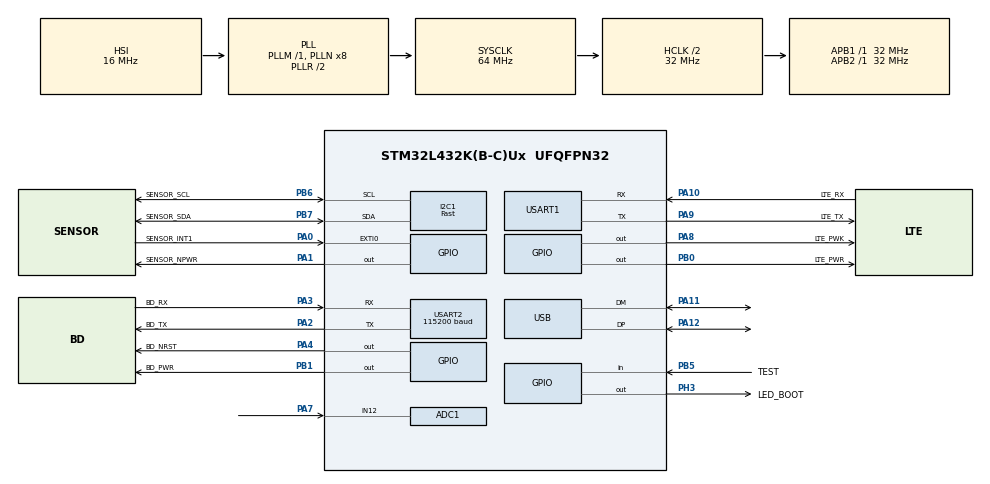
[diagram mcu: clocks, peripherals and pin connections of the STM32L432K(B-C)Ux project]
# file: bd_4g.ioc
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ADC1.Channel-0\#ChannelRegularConversion=ADC_CHANNEL_12
ADC1.Channel-1\#ChannelRegularConversion=ADC_CHANNEL_TEMPSENSOR
ADC1.Channel-2\#ChannelRegularConversion=ADC_CHANNEL_VBAT
ADC1.Channel-3\#ChannelRegularConversion=ADC_CHANNEL_VREFINT
ADC1.ClockPrescaler=ADC_CLOCK_ASYNC_DIV4
ADC1.ContinuousConvMode=ENABLE
ADC1.DMAContinuousRequests=ENABLE
ADC1.EOCSelection=ADC_EOC_SEQ_CONV
ADC1.EnableAnalogWatchDog1=false
ADC1.LowPowerAutoWait=DISABLE
ADC1.NbrOfConversion=4
ADC1.NbrOfConversionFlag=1
ADC1.OffsetNumber-0\#ChannelRegularConversion=ADC_OFFSET_NONE
ADC1.OffsetNumber-1\#ChannelRegularConversion=ADC_OFFSET_NONE
ADC1.OffsetNumber-2\#ChannelRegularConversion=ADC_OFFSET_NONE
ADC1.OffsetNumber-3\#ChannelRegularConversion=ADC_OFFSET_NONE
ADC1.Overrun=ADC_OVR_DATA_OVERWRITTEN
ADC1.OversamplingMode=ENABLE
ADC1.Rank-0\#ChannelRegularConversion=1
ADC1.Rank-1\#ChannelRegularConversion=2
ADC1.Rank-2\#ChannelRegularConversion=3
ADC1.Rank-3\#ChannelRegularConversion=4
ADC1.Ratio=ADC_OVERSAMPLING_RATIO_256
ADC1.RightBitShift=ADC_RIGHTBITSHIFT_8
ADC1.SamplingTime-0\#ChannelRegularConversion=ADC_SAMPLETIME_640CYCLES_5
ADC1.SamplingTime-1\#ChannelRegularConversion=ADC_SAMPLETIME_640CYCLES_5
ADC1.SamplingTime-2\#ChannelRegularConversion=ADC_SAMPLETIME_640CYCLES_5
ADC1.SamplingTime-3\#ChannelRegularConversion=ADC_SAMPLETIME_640CYCLES_5
ADC1.master=1
AL94.I-CUBE-USBD-COMPOSITE.1.0.3._STM32F1_DEVICE=true
AL94.I-CUBE-USBD-COMPOSITE.1.0.3._USBD_CDC_ACM_COUNT=2
AL94.I-CUBE-USBD-COMPOSITE.1.0.3._USBD_USE_CDC_ACM=true
CRC.CRCLength=CRC_POLYLENGTH_16B
CRC.DefaultInitValueUse=DEFAULT_INIT_VALUE_DISABLE
CRC.DefaultPolynomialUse=DEFAULT_POLYNOMIAL_DISABLE
CRC.GeneratingPolynomial=X12+X5+X0
Dma.ADC1.0.Direction=DMA_PERIPH_TO_MEMORY
Dma.ADC1.0.Instance=DMA1_Channel1
Dma.ADC1.0.MemDataAlignment=DMA_MDATAALIGN_HALFWORD
Dma.ADC1.0.MemInc=DMA_MINC_ENABLE
Dma.ADC1.0.Mode=DMA_CIRCULAR
Dma.ADC1.0.PeriphDataAlignment=DMA_PDATAALIGN_HALFWORD
Dma.ADC1.0.PeriphInc=DMA_PINC_DISABLE
Dma.ADC1.0.Priority=DMA_PRIORITY_LOW
Dma.I2C1_RX.3.Direction=DMA_PERIPH_TO_MEMORY
Dma.I2C1_RX.3.Instance=DMA2_Channel6
Dma.I2C1_RX.3.MemDataAlignment=DMA_MDATAALIGN_BYTE
Dma.I2C1_RX.3.MemInc=DMA_MINC_ENABLE
Dma.I2C1_RX.3.Mode=DMA_NORMAL
Dma.I2C1_RX.3.PeriphDataAlignment=DMA_PDATAALIGN_BYTE
Dma.I2C1_RX.3.PeriphInc=DMA_PINC_DISABLE
Dma.I2C1_RX.3.Priority=DMA_PRIORITY_LOW
Dma.I2C1_TX.4.Direction=DMA_MEMORY_TO_PERIPH
Dma.I2C1_TX.4.Instance=DMA2_Channel7
Dma.I2C1_TX.4.MemDataAlignment=DMA_MDATAALIGN_BYTE
Dma.I2C1_TX.4.MemInc=DMA_MINC_ENABLE
Dma.I2C1_TX.4.Mode=DMA_NORMAL
Dma.I2C1_TX.4.PeriphDataAlignment=DMA_PDATAALIGN_BYTE
Dma.I2C1_TX.4.PeriphInc=DMA_PINC_DISABLE
Dma.I2C1_TX.4.Priority=DMA_PRIORITY_LOW
Dma.Request0=ADC1
Dma.Request1=USART2_RX
Dma.Request2=USART2_TX
Dma.Request3=I2C1_RX
Dma.Request4=I2C1_TX
Dma.Request5=USART1_RX
Dma.Request6=USART1_TX
Dma.USART1_RX.5.Direction=DMA_PERIPH_TO_MEMORY
Dma.USART1_RX.5.Instance=DMA1_Channel5
Dma.USART1_RX.5.MemDataAlignment=DMA_MDATAALIGN_BYTE
Dma.USART1_RX.5.MemInc=DMA_MINC_ENABLE
Dma.USART1_RX.5.Mode=DMA_NORMAL
Dma.USART1_RX.5.PeriphDataAlignment=DMA_PDATAALIGN_BYTE
Dma.USART1_RX.5.PeriphInc=DMA_PINC_DISABLE
Dma.USART1_RX.5.Priority=DMA_PRIORITY_LOW
Dma.USART1_TX.6.Direction=DMA_MEMORY_TO_PERIPH
Dma.USART1_TX.6.Instance=DMA1_Channel4
Dma.USART1_TX.6.MemDataAlignment=DMA_MDATAALIGN_BYTE
Dma.USART1_TX.6.MemInc=DMA_MINC_ENABLE
Dma.USART1_TX.6.Mode=DMA_NORMAL
Dma.USART1_TX.6.PeriphDataAlignment=DMA_PDATAALIGN_BYTE
Dma.USART1_TX.6.PeriphInc=DMA_PINC_DISABLE
Dma.USART1_TX.6.Priority=DMA_PRIORITY_LOW
Dma.USART2_RX.1.Direction=DMA_PERIPH_TO_MEMORY
Dma.USART2_RX.1.Instance=DMA1_Channel6
Dma.USART2_RX.1.MemDataAlignment=DMA_MDATAALIGN_BYTE
Dma.USART2_RX.1.MemInc=DMA_MINC_ENABLE
Dma.USART2_RX.1.Mode=DMA_NORMAL
Dma.USART2_RX.1.PeriphDataAlignment=DMA_PDATAALIGN_BYTE
Dma.USART2_RX.1.PeriphInc=DMA_PINC_DISABLE
Dma.USART2_RX.1.Priority=DMA_PRIORITY_LOW
Dma.USART2_TX.2.Direction=DMA_MEMORY_TO_PERIPH
Dma.USART2_TX.2.Instance=DMA1_Channel7
Dma.USART2_TX.2.MemDataAlignment=DMA_MDATAALIGN_BYTE
Dma.USART2_TX.2.MemInc=DMA_MINC_ENABLE
Dma.USART2_TX.2.Mode=DMA_NORMAL
Dma.USART2_TX.2.PeriphDataAlignment=DMA_PDATAALIGN_BYTE
Dma.USART2_TX.2.PeriphInc=DMA_PINC_DISABLE
Dma.USART2_TX.2.Priority=DMA_PRIORITY_LOW
FREERTOS.Tasks01=boot,24,512,boot_thread,As weak,NULL,Dynamic,NULL,NULL
FREERTOS.configENABLE_FPU=1
FREERTOS.configRECORD_STACK_HIGH_ADDRESS=1
FREERTOS.configTIMER_TASK_PRIORITY=45
FREERTOS.configTIMER_TASK_STACK_DEPTH=512
FREERTOS.configTOTAL_HEAP_SIZE=28672
FREERTOS.configUSE_NEWLIB_REENTRANT=1
I2C1.I2C_Speed_Mode=I2C_Fast
I2C1.Timing=0x0060112F
IWDG.Prescaler=IWDG_PRESCALER_32
Mcu.Family=STM32L4
Mcu.Name=STM32L432K(B-C)Ux
Mcu.Package=UFQFPN32
NVIC.DMA1_Channel1_IRQn=true\:5\:0\:false\:false\:true\:true\:false\:true\:true
NVIC.DMA1_Channel4_IRQn=true\:5\:0\:false\:false\:true\:true\:false\:true\:true
NVIC.DMA1_Channel5_IRQn=true\:5\:0\:false\:false\:true\:true\:false\:true\:true
NVIC.DMA1_Channel6_IRQn=true\:5\:0\:false\:false\:true\:true\:false\:true\:true
NVIC.DMA1_Channel7_IRQn=true\:5\:0\:false\:false\:true\:true\:false\:true\:true
NVIC.DMA2_Channel6_IRQn=true\:5\:0\:false\:false\:true\:true\:false\:true\:true
NVIC.DMA2_Channel7_IRQn=true\:5\:0\:false\:false\:true\:true\:false\:true\:true
NVIC.EXTI0_IRQn=true\:5\:0\:false\:false\:true\:true\:true\:true\:true
NVIC.I2C1_ER_IRQn=true\:5\:0\:false\:false\:true\:true\:true\:true\:true
NVIC.I2C1_EV_IRQn=true\:5\:0\:false\:false\:true\:true\:true\:true\:true
NVIC.PriorityGroup=NVIC_PRIORITYGROUP_4
NVIC.TIM6_DAC_IRQn=true\:15\:0\:false\:false\:true\:false\:false\:true\:true
NVIC.TimeBase=TIM6_DAC_IRQn
NVIC.TimeBaseIP=TIM6
NVIC.USART1_IRQn=true\:5\:0\:false\:false\:true\:true\:true\:true\:true
NVIC.USART2_IRQn=true\:5\:0\:false\:false\:true\:true\:true\:true\:true
NVIC.USB_IRQn=true\:5\:0\:false\:false\:true\:true\:true\:true\:true
PA0.GPIO_Label=SENSOR_INT1
PA0.Signal=GPXTI0
PA1.GPIO_Label=SENSOR_NPWR
PA1.GPIO_PuPd=GPIO_PULLDOWN
PA1.Signal=GPIO_Output
PA10.GPIO_Label=LTE_RX
PA10.GPIO_Speed=GPIO_SPEED_FREQ_HIGH
PA10.Mode=Asynchronous
PA10.Signal=USART1_RX
PA11.Mode=Device
PA11.Signal=USB_DM
PA12.Mode=Device
PA12.Signal=USB_DP
PA13\ (JTMS-SWDIO).Mode=Serial_Wire
PA13\ (JTMS-SWDIO).Signal=SYS_JTMS-SWDIO
PA14\ (JTCK-SWCLK).Mode=Serial_Wire
PA14\ (JTCK-SWCLK).Signal=SYS_JTCK-SWCLK
PA2.GPIO_Label=BD_TX
PA2.Mode=Asynchronous
PA2.Signal=USART2_TX
PA3.GPIO_Label=BD_RX
PA3.Mode=Asynchronous
PA3.Signal=USART2_RX
PA4.GPIO_Label=BD_NRST
PA4.Signal=GPIO_Output
PA7.Signal=ADCx_IN12
PA8.GPIO_Label=LTE_PWK
PA8.Signal=GPIO_Output
PA9.GPIO_Label=LTE_TX
PA9.GPIO_Speed=GPIO_SPEED_FREQ_HIGH
PA9.Mode=Asynchronous
PA9.Signal=USART1_TX
PB0.GPIO_Label=LTE_PWR
PB0.Signal=GPIO_Output
PB1.GPIO_Label=BD_PWR
PB1.Signal=GPIO_Output
PB5.GPIO_Label=TEST
PB5.Signal=GPIO_Input
PB6.GPIO_FM6=SYSCFG_FASTMODEPLUS_PB6
PB6.GPIO_Label=SENSOR_SCL
PB6.GPIO_Pu=GPIO_PULLUP
PB6.Mode=I2C
PB6.Signal=I2C1_SCL
PB7.GPIO_FM7=SYSCFG_FASTMODEPLUS_PB7
PB7.GPIO_Label=SENSOR_SDA
PB7.GPIO_Pu=GPIO_PULLUP
PB7.Mode=I2C
PB7.Signal=I2C1_SDA
PC14-OSC32_IN\ (PC14).Mode=LSE-External-Oscillator
PC14-OSC32_IN\ (PC14).Signal=RCC_OSC32_IN
PC15-OSC32_OUT\ (PC15).Mode=LSE-External-Oscillator
PC15-OSC32_OUT\ (PC15).Signal=RCC_OSC32_OUT
PH3-BOOT0.GPIO_Label=LED_BOOT
PH3-BOOT0.Signal=GPIO_Output
ProjectManager.HeapSize=0x1200
ProjectManager.StackSize=0x800
ProjectManager.TargetToolchain=STM32CubeIDE
RCC.ADCFreq_Value=64000000
RCC.AHBCLKDivider=RCC_SYSCLK_DIV2
RCC.AHBFreq_Value=32000000
RCC.APB1Freq_Value=32000000
RCC.APB1TimFreq_Value=32000000
RCC.APB2Freq_Value=32000000
RCC.APB2TimFreq_Value=32000000
RCC.CK48CLockSelection=RCC_USBCLKSOURCE_HSI48
RCC.CortexFreq_Value=32000000
RCC.HCLKFreq_Value=32000000
RCC.HSE_VALUE=8000000
RCC.HSI48_VALUE=48000000
RCC.HSI_VALUE=16000000
RCC.LSE_Drive_Capability=RCC_LSEDRIVE_LOW
RCC.MSI_VALUE=4000000
RCC.PLLSourceVirtual=RCC_PLLSOURCE_HSI
RCC.PREFETCH_ENABLE=1
RCC.RTCClockSelection=RCC_RTCCLKSOURCE_LSE
RCC.SYSCLKFreq_VALUE=64000000
RCC.SYSCLKSource=RCC_SYSCLKSOURCE_PLLCLK
RCC.USBFreq_Value=48000000
RCC.VCOOutputFreq_Value=128000000
RCC.VDD_VALUE=2
RTC.WakeUpClock=RTC_WAKEUPCLOCK_CK_SPRE_17BITS
SH.ADCx_IN12.0=ADC1_IN12,IN12-Single-Ended
STMicroelectronics.X-CUBE-ALGOBUILD.1.4.0.LibraryCcDSPOoLibraryJjDSPOoLibrary=true
USART1.VirtualMode-Asynchronous=VM_ASYNC
USART2.BaudRate=115200
USART2.VirtualMode-Asynchronous=VM_ASYNC
USB_DEVICE.APP_RX_DATA_SIZE=512
USB_DEVICE.APP_TX_DATA_SIZE=512
USB_DEVICE.CLASS_NAME_FS=CDC
USB_DEVICE.VirtualMode=Cdc
USB_DEVICE.VirtualModeFS=Cdc_FS
VP_ADC1_TempSens_Input.Mode=IN-TempSens
VP_ADC1_Vbat_Input.Mode=IN-Vbat
VP_ADC1_Vref_Input.Mode=IN-Vrefint
VP_CRC_VS_CRC.Mode=CRC_Activate
VP_FREERTOS_VS_CMSIS_V2.Mode=CMSIS_V2
VP_IWDG_VS_IWDG.Mode=IWDG_Activate
VP_RTC_VS_RTC_Activate.Mode=RTC_Enabled
VP_RTC_VS_RTC_WakeUp_intern.Mode=WakeUp
VP_STMicroelectronics.X-CUBE-ALGOBUILD_VS_DSPOoLibraryJjLibrary_1.4.0_1.4.0.Mode=DSPOoLibraryJjLibrary
VP_SYS_VS_tim6.Mode=TIM6
VP_USB_DEVICE_VS_USB_DEVICE_CDC_FS.Mode=CDC_FS
board=custom

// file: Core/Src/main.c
/* USER CODE BEGIN Header */
/**
 ******************************************************************************
 * @file           : main.c
 * @brief          : Main program body
 ******************************************************************************
 * @attention
 *
 * Copyright (c) 2025 STMicroelectronics.
 * All rights reserved.
 *
 * This software is licensed under terms that can be found in the LICENSE file
 * in the root directory of this software component.
 * If no LICENSE file comes with this software, it is provided AS-IS.
 *
 ******************************************************************************
 */
/* USER CODE END Header */
#include "main.h"
#include "cmsis_os.h"
#include "adc.h"
#include "crc.h"
#include "dma.h"
#include "i2c.h"
#include "iwdg.h"
#include "rtc.h"
#include "usart.h"
#include "usb_device.h"
#include "gpio.h"

/* USER CODE BEGIN Includes */
int INT1_PIN_STATE = 0;
/* USER CODE END Includes */

void SystemClock_Config(void);
void MX_FREERTOS_Init(void);
/* USER CODE BEGIN PFP */
void freertos_heap_regions_init(void);
/* USER CODE END PFP */

int main(void)
{

  /* MCU Configuration--------------------------------------------------------*/

  /* Reset of all peripherals, Initializes the Flash interface and the Systick. */
  HAL_Init();

  /* Configure the system clock */
  SystemClock_Config();

  /* Initialize all configured peripherals */
  MX_GPIO_Init();
  MX_DMA_Init();
  MX_I2C1_Init();
  MX_USART1_UART_Init();
  MX_USART2_UART_Init();
  MX_ADC1_Init();
  MX_CRC_Init();
  MX_RTC_Init();
  MX_IWDG_Init();
  /* USER CODE BEGIN 2 */
	if (HAL_GPIO_ReadPin(SENSOR_INT1_GPIO_Port, SENSOR_INT1_Pin)
			== GPIO_PIN_SET)
		INT1_PIN_STATE = 1;
  /* USER CODE END 2 */

  /* Init scheduler */
  /* heap_5：先登记 SRAM2+SRAM1 堆区，再创建任何 RTOS 对象 */
  freertos_heap_regions_init();
  osKernelInitialize();

  /* Call init function for freertos objects (in cmsis_os2.c) */
  MX_FREERTOS_Init();

  /* Start scheduler */
  osKernelStart();

  /* We should never get here as control is now taken by the scheduler */

  /* Infinite loop */
	while (1) {

	}
}

void SystemClock_Config(void)
{
  RCC_OscInitTypeDef RCC_OscInitStruct = {0};
  RCC_ClkInitTypeDef RCC_ClkInitStruct = {0};

  /** Configure the main internal regulator output voltage
  */
  if (HAL_PWREx_ControlVoltageScaling(PWR_REGULATOR_VOLTAGE_SCALE1) != HAL_OK)
  {
    Error_Handler();
  }

  /** Configure LSE Drive Capability
  */
  HAL_PWR_EnableBkUpAccess();
  __HAL_RCC_LSEDRIVE_CONFIG(RCC_LSEDRIVE_LOW);

  /** Initializes the RCC Oscillators according to the specified parameters
  * in the RCC_OscInitTypeDef structure.
  */
  RCC_OscInitStruct.OscillatorType = RCC_OSCILLATORTYPE_HSI48|RCC_OSCILLATORTYPE_HSI
                              |RCC_OSCILLATORTYPE_LSI|RCC_OSCILLATORTYPE_LSE;
  RCC_OscInitStruct.LSEState = RCC_LSE_ON;
  RCC_OscInitStruct.HSIState = RCC_HSI_ON;
  RCC_OscInitStruct.HSI48State = RCC_HSI48_ON;
  RCC_OscInitStruct.HSICalibrationValue = RCC_HSICALIBRATION_DEFAULT;
  RCC_OscInitStruct.LSIState = RCC_LSI_ON;
  RCC_OscInitStruct.PLL.PLLState = RCC_PLL_ON;
  RCC_OscInitStruct.PLL.PLLSource = RCC_PLLSOURCE_HSI;
  RCC_OscInitStruct.PLL.PLLM = 1;
  RCC_OscInitStruct.PLL.PLLN = 8;
  RCC_OscInitStruct.PLL.PLLP = RCC_PLLP_DIV7;
  RCC_OscInitStruct.PLL.PLLQ = RCC_PLLQ_DIV2;
  RCC_OscInitStruct.PLL.PLLR = RCC_PLLR_DIV2;
  if (HAL_RCC_OscConfig(&RCC_OscInitStruct) != HAL_OK)
  {
    Error_Handler();
  }

  /** Initializes the CPU, AHB and APB buses clocks
  */
  RCC_ClkInitStruct.ClockType = RCC_CLOCKTYPE_HCLK|RCC_CLOCKTYPE_SYSCLK
                              |RCC_CLOCKTYPE_PCLK1|RCC_CLOCKTYPE_PCLK2;
  RCC_ClkInitStruct.SYSCLKSource = RCC_SYSCLKSOURCE_PLLCLK;
  RCC_ClkInitStruct.AHBCLKDivider = RCC_SYSCLK_DIV2;
  RCC_ClkInitStruct.APB1CLKDivider = RCC_HCLK_DIV1;
  RCC_ClkInitStruct.APB2CLKDivider = RCC_HCLK_DIV1;

  if (HAL_RCC_ClockConfig(&RCC_ClkInitStruct, FLASH_LATENCY_1) != HAL_OK)
  {
    Error_Handler();
  }
}

void HAL_TIM_PeriodElapsedCallback(TIM_HandleTypeDef *htim)
{
  if (htim->Instance == TIM6)
  {
    HAL_IncTick();
  }
}

void Error_Handler(void)
{
	__disable_irq();
	while (1) {
	}
}

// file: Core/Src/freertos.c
/* USER CODE BEGIN Header */
/**
  ******************************************************************************
  * File Name          : freertos.c
  * Description        : Code for freertos applications
  ******************************************************************************
  * @attention
  *
  * Copyright (c) 2025 STMicroelectronics.
  * All rights reserved.
  *
  * This software is licensed under terms that can be found in the LICENSE file
  * in the root directory of this software component.
  * If no LICENSE file comes with this software, it is provided AS-IS.
  *
  ******************************************************************************
  */
/* USER CODE END Header */

#include "FreeRTOS.h"
#include "task.h"
#include "main.h"
#include "cmsis_os.h"

/* Definitions for boot */
osThreadId_t bootHandle;
const osThreadAttr_t boot_attributes = {
  .name = "boot",
  /* 初始化路径较重（NVM/传感器/Solution），保持 512 words */
  .stack_size = 512 * 4,
  .priority = (osPriority_t) osPriorityNormal,
};

void boot_thread(void *argument);

extern void MX_USB_DEVICE_Init(void);
void MX_FREERTOS_Init(void); /* (MISRA C 2004 rule 8.1) */

void MX_FREERTOS_Init(void) {

  /* Create the thread(s) */
  /* creation of boot */
  bootHandle = osThreadNew(boot_thread, NULL, &boot_attributes);

}

__weak void boot_thread(void *argument)
{
  /* init code for USB_DEVICE */
  MX_USB_DEVICE_Init();
  for(;;)
  {
    osDelay(1);
  }
}

/* USER CODE BEGIN Application */

#include "SEGGER_RTT.h"

void vApplicationMallocFailedHook(void)
{
  SEGGER_RTT_printf(0, "FATAL: FreeRTOS malloc failed, free=%u\r\n",
		    (unsigned) xPortGetFreeHeapSize());
  taskDISABLE_INTERRUPTS();
  for (;;)
    {
    }
}

void vApplicationStackOverflowHook(TaskHandle_t xTask, char *pcTaskName)
{
  (void) xTask;
  SEGGER_RTT_printf(0, "FATAL: stack overflow task=%s\r\n",
		    pcTaskName != NULL ? pcTaskName : "?");
  taskDISABLE_INTERRUPTS();
  for (;;)
    {
    }
}

/* USER CODE END Application */
